# S32K342_M7 register map
Vendor: NXP Semiconductors; File version: 1.5
CPU: CM7 r0p1, little endian, MPU, FPU, VTOR, 4 interrupt priority bits
Registers are 32-bit, read-write, reset 0x0 unless marked. A register's access mark holds for its fields unless they carry their own. Offsets are from the block's base; [hi:lo] are bit positions; 'fields as' and 'values as' point back to an identical list.

## PMC
Base 0x402E8000
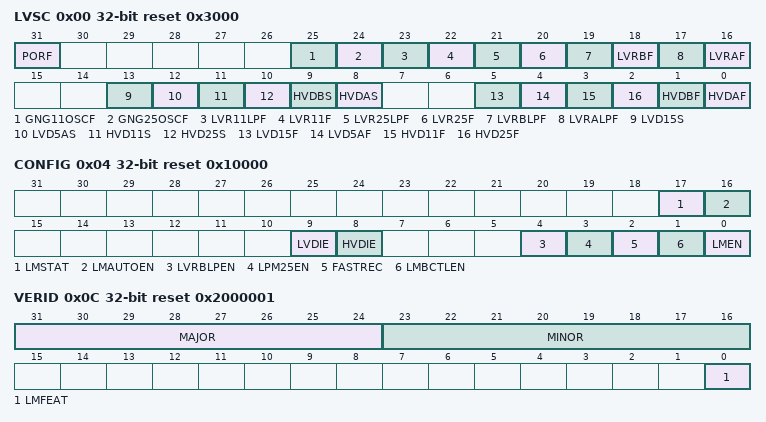
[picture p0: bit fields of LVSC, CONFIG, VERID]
0x00 LVSC reset 0x3000 (reset mask 0x7C00FFFF) — Low Voltage Status and Control Register
  [31] PORF write-1-clears — POR flag
    0=NO_EVENT (No power-on reset event has occurred); 1=EVENT (Power-on reset event has occurred)
  [25] GNG11OSCF write-1-clears — Go/NoGo detect flag on Osc part of V11 domain
    0=NO_EVENT (No event has occurred); 1=EVENT (NoGo event has occurred)
  [24] GNG25OSCF write-1-clears — GO/NoGo detect flag on Osc part of V25 domain
    values as GNG11OSCF
  [23] LVR11LPF write-1-clears — LVR11LP flag on V11 domain
    0=NO_EVENT (No low-voltage reset event has occurred); 1=EVENT (Low-voltage reset event has occurred)
  [22] LVR11F write-1-clears — LVR11 flag on V11 domain in FPM
    values as LVR11LPF
  [21] LVR25LPF write-1-clears — LVR25LP flag on V25 domain
    values as LVR11LPF
  [20] LVR25F write-1-clears — LVR25 flag on V25 domain in FPM
    values as LVR11LPF
  [19] LVRBLPF write-1-clears — LVRBLP flag on VDD_HV_B domain
    values as LVR11LPF
  [18] LVRBF write-1-clears — LVRB flag on VDD_HV_B domain in FPM
    values as LVR11LPF
  [17] LVRALPF write-1-clears — LVRALP flag on VDD_HV_A domain
    values as LVR11LPF
  [16] LVRAF write-1-clears — LVRA flag on VDD_HV_A domain in FPM
    values as LVR11LPF
  [13] LVD15S ro — LVD15 status on V15 domain in FPM
    0=VOLTAGE_GOOD (Voltage on V15 is above low-voltage detect threshold or LPM.); 1=VOLTAGE_TOO_LOW (Voltage on V15 is below low-voltage detect threshold and FPM.)
  [12] LVD5AS ro — LVD5A status on VDD_HV_A domain in FPM
    0=VOLTAGE_HIGH_TYP5 (Voltage on VDD_HV_A is above low-voltage detect threshold); 1=VOLTAGE_LOW_TYP33 (Voltage on VDD_HV_A is below low-voltage detect threshold)
  [11] HVD11S ro — HVD11 status on V11 domain in FPM
    0=VOLTAGE_GOOD (Voltage on V11 is below high-voltage detect threshold or LPM.); 1=VOLTAGE_TOO_HIGH (Voltage on V11 is above high-voltage detect threshold and FPM.)
  [10] HVD25S ro — HVD25 status on V25 domain in FPM
    0=VOLTAGE_GOOD (Voltage on V25 is below high-voltage detect threshold or LPM.); 1=VOLTAGE_TOO_HIGH (Voltage on V25 is above high-voltage detect threshold and FPM.)
  [9] HVDBS ro — HVDB status on VDD_HV_B domain in FPM
    0=VOLTAGE_GOOD (Voltage on VDD_HV_B is below high-voltage detect threshold or LPM.); 1=VOLTAGE_TOO_HIGH (Voltage on VDD_HV_B is above high-voltage detect threshold and FPM.)
  [8] HVDAS ro — HVDA status on VDD_HV_A domain in FPM
    0=VOLTAGE_GOOD (Voltage on VDD_HV_A is below high-voltage detect threshold or LPM.); 1=VOLTAGE_TOO_HIGH (Voltage on VDD_HV_A is above high-voltage detect threshold and FPM.)
  [5] LVD15F write-1-clears — LVD15 flag on V15 domain in FPM
    0=NO_EVENT (LVD15S has not changed.); 1=EVENT (LVD15S has changed.)
  [4] LVD5AF write-1-clears — LVD5A flag on VDD_HV_A domain in FPM
    0=NO_EVENT (LVD5AS has not changed.); 1=EVENT (LVD5AS has changed.)
  [3] HVD11F write-1-clears — HVD11 flag on V11 domain in FPM
    0=NO_EVENT (HVD11S has not changed.); 1=EVENT (HVD11S has changed.)
  [2] HVD25F write-1-clears — HVD25 flag on V25 domain in FPM
    0=NO_EVENT (HVD25S has not changed.); 1=EVENT (HVD25S has changed.)
  [1] HVDBF write-1-clears — HVDB flag on VDD_HV_B domain in FPM
    0=NO_EVENT (HVDBS has not changed.); 1=EVENT (HVDBS has changed.)
  [0] HVDAF write-1-clears — HVDA flag on VDD_HV_A domain in FPM
    0=NO_EVENT (HVDAS has not changed.); 1=EVENT (HVDAS has changed.)
0x04 CONFIG reset 0x10000 (reset mask 0xFFFDFFFF) — PMC Configuration Register
  [17] LMSTAT ro — Last Mile regulator status bit
    0=DISABLE (Last Mile Regulator is off); 1=ENABLE (Last Mile Regulator is on)
  [16] LMAUTOEN — Last Mile regulator auto turn over bit
    0=DISABLE (Auto turnover disabled); 1=ENABLE (Auto turnover enabled)
  [9] LVDIE — Low voltage detect interrupt enable
    0=DISABLE (LVD hardware interrupt is disabled (use polling).); 1=ENABLE (Request an LVD hardware interrupt when LVDA5F=1 or LVD15F=1.)
  [8] HVDIE — High voltage detect interrupt enable
    0=DISABLE (HVD hardware interrupt is disabled (use polling).); 1=ENABLE (Request an HVD hardware interrupt when HVDAF=1, HVDBF=1, HVD25F=1, or HVD11F=1.)
  [4] LVRBLPEN — LVRBLP enable bit during LPM
    0=DISABLE (Low-voltage reset detection is disabled in LPM.); 1=ENABLE (Low-voltage reset detection is enabled in LPM.)
  [3] LPM25EN — V25 domain enable bit during LPM
    0=DISABLE (V25 regulator and LVR25LP are disabled in LPM.); 1=ENABLE (V25 regulator and LVR25LP are enabled in LPM.)
  [2] FASTREC — Fast recovery from LPM enable bit
    0=DISABLE (Normal recovery time from LPM); 1=ENABLE (Fast recovery time from LPM)
  [1] LMBCTLEN — Last Mile regulator base control enable bit
    0=DISABLE (External BCTL regulator for V15 disabled); 1=ENABLE (External BCTL regulator for V15 enabled)
  [0] LMEN — Last Mile regulator enable bit
    0=DISABLE (Last Mile regulator is disabled.); 1=ENABLE (Last Mile regulator is enabled.)
0x0C VERID ro reset 0x2000001 — Version ID register
  [31:24] MAJOR — Major version number
  [23:16] MINOR — Minor version number
  [0] LMFEAT — Last Mile Regulator Feature
    0=DISABLE (No Last Mile regulator); 1=ENABLE (Last Mile regulator (1.5V to 1.1V) is available)
